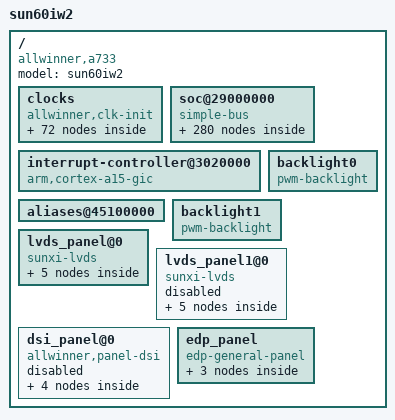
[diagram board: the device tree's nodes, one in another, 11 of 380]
/dts-v1/;

/ {
	model = "sun60iw2";
	compatible = "allwinner,a733", "arm,sun60iw2p1";
	#address-cells = <0x02>;
	#size-cells = <0x02>;

	clocks {
		compatible = "allwinner,clk-init";
		device_type = "clocks";
		#address-cells = <0x02>;
		#size-cells = <0x02>;
		ranges;
		reg = <0x00 0x2002000 0x00 0x2000 0x00 0x7010000 0x00 0x400>;

		pll_periph0 {
			#clock-cells = <0x00>;
			compatible = "allwinner,pll-clock";
			assigned-clock-rates = <0x23c34600>;
			lock-mode = "new";
			clock-output-names = "pll_periph0";
			phandle = <0x07>;
		};

		pll_periph0_2x {
			#clock-cells = <0x00>;
			compatible = "allwinner,pll-clock";
			lock-mode = "new";
			clock-output-names = "pll_periph0_2x";
			phandle = <0x01>;
		};

		pll_periph0_800m {
			#clock-cells = <0x00>;
			compatible = "allwinner,pll-clock";
			lock-mode = "new";
			clock-output-names = "pll_periph0_800m";
		};

		pll_periph0_600m {
			#clock-cells = <0x00>;
			compatible = "allwinner,fixed-factor-clock";
			clocks = <0x01>;
			clock-mult = <0x01>;
			clock-div = <0x02>;
			clock-output-names = "pll_periph0_600m";
			phandle = <0x02>;
		};

		pll_periph0_480m {
			#clock-cells = <0x00>;
			compatible = "allwinner,pll-clock";
			lock-mode = "new";
			clock-output-names = "pll_periph0_480m";
		};

		pll_periph0_400m {
			#clock-cells = <0x00>;
			compatible = "allwinner,fixed-factor-clock";
			clocks = <0x01>;
			clock-mult = <0x01>;
			clock-div = <0x03>;
			clock-output-names = "pll_periph0_400m";
			phandle = <0x03>;
		};

		pll_periph0_300m {
			#clock-cells = <0x00>;
			compatible = "allwinner,fixed-factor-clock";
			clocks = <0x02>;
			clock-mult = <0x01>;
			clock-div = <0x02>;
			clock-output-names = "pll_periph0_300m";
			phandle = <0x04>;
		};

		pll_periph0_200m {
			#clock-cells = <0x00>;
			compatible = "allwinner,fixed-factor-clock";
			clocks = <0x03>;
			clock-mult = <0x01>;
			clock-div = <0x02>;
			clock-output-names = "pll_periph0_200m";
		};

		pll_periph0_150m {
			#clock-cells = <0x00>;
			compatible = "allwinner,fixed-factor-clock";
			clocks = <0x04>;
			clock-mult = <0x01>;
			clock-div = <0x02>;
			clock-output-names = "pll_periph0_150m";
			phandle = <0x11>;
		};

		pll_periph1_2x {
			#clock-cells = <0x00>;
			compatible = "allwinner,pll-clock";
			lock-mode = "new";
			clock-output-names = "pll_periph1_2x";
			phandle = <0x05>;
		};

		pll_periph1_800m {
			#clock-cells = <0x00>;
			compatible = "allwinner,pll-clock";
			lock-mode = "new";
			clock-output-names = "pll_periph1_800m";
		};

		pll_periph1_600m {
			#clock-cells = <0x00>;
			compatible = "allwinner,fixed-factor-clock";
			clocks = <0x05>;
			clock-mult = <0x01>;
			clock-div = <0x02>;
			clock-output-names = "pll_periph1_600m";
			phandle = <0x06>;
		};

		pll_periph1_400m {
			#clock-cells = <0x00>;
			compatible = "allwinner,fixed-factor-clock";
			clocks = <0x05>;
			clock-mult = <0x01>;
			clock-div = <0x03>;
			clock-output-names = "pll_periph1_400m";
		};

		pll_periph1_300m {
			#clock-cells = <0x00>;
			compatible = "allwinner,fixed-factor-clock";
			clocks = <0x06>;
			clock-mult = <0x01>;
			clock-div = <0x02>;
			clock-output-names = "pll_periph1_300m";
		};

		pll_video2 {
			#clock-cells = <0x00>;
			compatible = "allwinner,pll-clock";
			lock-mode = "new";
			clock-output-names = "pll_video2";
			phandle = <0x0c>;
		};

		pll_periph0x2 {
			#clock-cells = <0x00>;
			compatible = "allwinner,fixed-factor-clock";
			clocks = <0x07>;
			clock-mult = <0x02>;
			clock-div = <0x01>;
			clock-output-names = "pll_periph0x2";
			phandle = <0x0a>;
		};

		pll_video0x4 {
			#clock-cells = <0x00>;
			compatible = "allwinner,pll-clock";
			lock-mode = "new";
			clock-output-names = "pll_video0x4";
		};

		pll_video0x3 {
			#clock-cells = <0x00>;
			compatible = "allwinner,pll-clock";
			lock-mode = "new";
			clock-output-names = "pll_video0x3";
		};

		pll_video1x4 {
			#clock-cells = <0x00>;
			compatible = "allwinner,pll-clock";
			lock-mode = "new";
			clock-output-names = "pll_video1x4";
			phandle = <0x0f>;
		};

		pll_video1x3 {
			#clock-cells = <0x00>;
			compatible = "allwinner,pll-clock";
			lock-mode = "new";
			clock-output-names = "pll_video1x3";
		};

		pll_video2x4 {
			#clock-cells = <0x00>;
			compatible = "allwinner,pll-clock";
			lock-mode = "new";
			clock-output-names = "pll_video2x4";
			phandle = <0x10>;
		};

		pll_dex4 {
			#clock-cells = <0x00>;
			compatible = "allwinner,pll-clock";
			lock-mode = "new";
			clock-output-names = "pll_dex4";
		};

		pll_dex3 {
			#clock-cells = <0x00>;
			compatible = "allwinner,pll-clock";
			lock-mode = "new";
			clock-output-names = "pll_dex3";
			phandle = <0x08>;
		};

		de0 {
			#clock-cells = <0x00>;
			compatible = "allwinner,periph-clock";
			clock-output-names = "de0";
			assigned-clock-parents = <0x08>;
			assigned-clock-rates = <0x23c34600>;
			assigned-clocks = <0x09>;
			phandle = <0x09>;
		};

		de_rst_sys {
			#clock-cells = <0x00>;
			compatible = "allwinner,periph-clock";
			clock-output-names = "de_rst_sys";
		};

		ee {
			#clock-cells = <0x00>;
			compatible = "allwinner,periph-clock";
			assigned-clock-parents = <0x0a>;
			assigned-clock-rates = <0x11e1a300>;
			assigned-clocks = <0x0b>;
			clock-output-names = "ee";
			phandle = <0x0b>;
		};

		panel {
			#clock-cells = <0x00>;
			compatible = "allwinner,periph-clock";
			assigned-clock-parents = <0x0c>;
			assigned-clock-rates = <0x1c9c380>;
			assigned-clocks = <0x0d>;
			clock-output-names = "panel";
			phandle = <0x0d>;
		};

		edp {
			#clock-cells = <0x00>;
			compatible = "allwinner,periph-clock";
			assigned-clocks = <0x0e>;
			assigned-clock-parents = <0x0f>;
			clock-output-names = "edp";
			phandle = <0x0e>;
		};

		sdmmc0_mod {
			#clock-cells = <0x00>;
			compatible = "allwinner,periph-clock";
			clock-output-names = "sdmmc0_mod";
			phandle = <0x99>;
		};

		sdmmc0_bus {
			#clock-cells = <0x00>;
			compatible = "allwinner,periph-clock";
			clock-output-names = "sdmmc0_bus";
			phandle = <0x9b>;
		};

		sdmmc0_rst {
			#clock-cells = <0x00>;
			compatible = "allwinner,periph-clock";
			clock-output-names = "sdmmc0_rst";
			phandle = <0x9a>;
		};

		sdmmc1_mod {
			#clock-cells = <0x00>;
			compatible = "allwinner,periph-clock";
			clock-output-names = "sdmmc1_mod";
		};

		sdmmc2_mod {
			#clock-cells = <0x00>;
			compatible = "allwinner,periph-clock";
			clock-output-names = "sdmmc2_mod";
			phandle = <0x9c>;
		};

		sdmmc2_bus {
			#clock-cells = <0x00>;
			compatible = "allwinner,periph-clock";
			clock-output-names = "sdmmc2_bus";
			phandle = <0x9e>;
		};

		sdmmc2_rst {
			#clock-cells = <0x00>;
			compatible = "allwinner,periph-clock";
			clock-output-names = "sdmmc2_rst";
			phandle = <0x9d>;
		};

		sdmmc3_mod {
			#clock-cells = <0x00>;
			compatible = "allwinner,periph-clock";
			clock-output-names = "sdmmc3_mod";
		};

		dpss_top0 {
			#clock-cells = <0x00>;
			compatible = "allwinner,periph-clock";
			clock-output-names = "dpss_top0";
			phandle = <0x63>;
		};

		dpss_top1 {
			#clock-cells = <0x00>;
			compatible = "allwinner,periph-clock";
			clock-output-names = "dpss_top1";
			phandle = <0x64>;
		};

		video_out0 {
			#clock-cells = <0x00>;
			compatible = "allwinner,periph-clock";
			clock-output-names = "video_out0";
		};

		video_out1 {
			#clock-cells = <0x00>;
			compatible = "allwinner,periph-clock";
			clock-output-names = "video_out1";
		};

		tcon_lcd0 {
			#clock-cells = <0x00>;
			compatible = "allwinner,periph-clock";
			clock-output-names = "tcon_lcd0";
			phandle = <0x65>;
		};

		tcon_lcd1 {
			#clock-cells = <0x00>;
			compatible = "allwinner,periph-clock";
			clock-output-names = "tcon_lcd1";
			phandle = <0x6b>;
		};

		tcon_lcd2 {
			#clock-cells = <0x00>;
			compatible = "allwinner,periph-clock";
			assigned-clock-parents = <0x10>;
			clock-output-names = "tcon_lcd2";
			phandle = <0x6d>;
		};

		tcon_tv0 {
			#clock-cells = <0x00>;
			compatible = "allwinner,periph-clock";
			clock-output-names = "tcon_tv0";
			phandle = <0x83>;
		};

		tcon_tv1 {
			#clock-cells = <0x00>;
			compatible = "allwinner,periph-clock";
			clock-output-names = "tcon_tv1";
			phandle = <0x86>;
		};

		lvds0 {
			#clock-cells = <0x00>;
			compatible = "allwinner,periph-clock";
			clock-output-names = "lvds0";
			phandle = <0x7b>;
		};

		lvds1 {
			#clock-cells = <0x00>;
			compatible = "allwinner,periph-clock";
			clock-output-names = "lvds1";
			phandle = <0x7f>;
		};

		mipi_dsi0 {
			#clock-cells = <0x00>;
			compatible = "allwinner,periph-clock";
			assigned-clock-parents = <0x11>;
			assigned-clock-rates = <0x8f0d180>;
			clock-output-names = "mipi_dsi0";
			phandle = <0x70>;
		};

		mipi_dsi1 {
			#clock-cells = <0x00>;
			compatible = "allwinner,periph-clock";
			assigned-clock-parents = <0x11>;
			assigned-clock-rates = <0x8f0d180>;
			clock-output-names = "mipi_dsi1";
			phandle = <0x78>;
		};

		mipi_dsc {
			#clock-cells = <0x00>;
			compatible = "allwinner,periph-clock";
			clock-output-names = "mipi_dsc";
			phandle = <0x71>;
		};

		mipi_dsi_combphy0 {
			#clock-cells = <0x00>;
			compatible = "allwinner,periph-clock";
			clock-output-names = "mipi_dsi_combphy0";
		};

		mipi_dsi_combphy1 {
			#clock-cells = <0x00>;
			compatible = "allwinner,periph-clock";
			clock-output-names = "mipi_dsi_combphy1";
		};

		hdmi_tv {
			#clock-cells = <0x00>;
			compatible = "allwinner,periph-clock";
			clock-output-names = "hdmi_tv";
		};

		hdmi_gate {
			#clock-cells = <0x00>;
			compatible = "allwinner,periph-clock";
			clock-output-names = "hdmi_gate";
			phandle = <0x8d>;
		};

		hdmi_sfr {
			#clock-cells = <0x00>;
			compatible = "allwinner,periph-clock";
			clock-output-names = "hdmi_sfr";
			phandle = <0x8e>;
		};

		hdmi_main_rst {
			#clock-cells = <0x00>;
			compatible = "allwinner,periph-clock";
			clock-output-names = "hdmi_main_rst";
			phandle = <0x8f>;
		};

		hdmi_hdcp_rst {
			#clock-cells = <0x00>;
			compatible = "allwinner,periph-clock";
			clock-output-names = "hdmi_hdcp_rst";
		};

		hdmi_sub_rst {
			#clock-cells = <0x00>;
			compatible = "allwinner,periph-clock";
			clock-output-names = "hdmi_sub_rst";
			phandle = <0x90>;
		};

		eink_panel {
			#clock-cells = <0x00>;
			compatible = "allwinner,periph-clock";
			clock-output-names = "eink_panel";
		};

		eink {
			#clock-cells = <0x00>;
			compatible = "allwinner,periph-clock";
			clock-output-names = "eink";
		};

		serdes_phy_cfg {
			#clock-cells = <0x00>;
			compatible = "allwinner,periph-clock";
			clock-output-names = "serdes_phy_cfg";
			phandle = <0x43>;
		};

		dcxo_serdes0_gate {
			#clock-cells = <0x00>;
			compatible = "allwinner,periph-clock";
			clock-output-names = "dcxo_serdes0_gate";
			phandle = <0x44>;
		};

		dcxo_serdes1_gate {
			#clock-cells = <0x00>;
			compatible = "allwinner,periph-clock";
			clock-output-names = "dcxo_serdes1_gate";
			phandle = <0x45>;
		};

		gmac0 {
			#clock-cells = <0x00>;
			compatible = "allwinner,periph-clock";
			clock-output-names = "gmac0";
			phandle = <0x93>;
		};

		gmac0_axi {
			#clock-cells = <0x00>;
			compatible = "allwinner,periph-clock";
			clock-output-names = "gmac0_axi";
			phandle = <0x92>;
		};

		gmac1 {
			#clock-cells = <0x00>;
			compatible = "allwinner,periph-clock";
			clock-output-names = "gmac1";
			phandle = <0x97>;
		};

		gmac1_axi {
			#clock-cells = <0x00>;
			compatible = "allwinner,periph-clock";
			clock-output-names = "gmac1_axi";
			phandle = <0x96>;
		};

		gmac0_mbus {
			#clock-cells = <0x00>;
			compatible = "allwinner,periph-clock";
			clock-output-names = "gmac0_mbus";
			phandle = <0x91>;
		};

		gmac1_mbus {
			#clock-cells = <0x00>;
			compatible = "allwinner,periph-clock";
			clock-output-names = "gmac1_mbus";
			phandle = <0x95>;
		};

		gmac0_phy {
			#clock-cells = <0x00>;
			compatible = "allwinner,periph-clock";
			clock-output-names = "gmac0_phy";
			assigned-clock-parents = <0x11>;
			assigned-clock-rates = <0x17d7840>;
			assigned-clocks = <0x12>;
			phandle = <0x12>;
		};

		gmac1_phy {
			#clock-cells = <0x00>;
			compatible = "allwinner,periph-clock";
			clock-output-names = "gmac1_phy";
			assigned-clock-parents = <0x11>;
			assigned-clock-rates = <0x17d7840>;
			assigned-clocks = <0x13>;
			phandle = <0x13>;
		};

		gmac_ptp {
			#clock-cells = <0x00>;
			compatible = "allwinner,periph-clock";
			clock-output-names = "gmac_ptp";
		};
	};

	soc@29000000 {
		compatible = "simple-bus";
		#address-cells = <0x02>;
		#size-cells = <0x02>;

		power_sply@4500000c {
			device_type = "power_sply";
			ntc_status = <0x02>;
			battery_exist = <0x00>;
		};

		power_delay@4500024 {
			device_type = "power_delay";
		};

		platform@45000004 {
			device_type = "platform";
			eraseflag = <0x01>;
			next_work = <0x03>;
			debug_mode = <0x04>;
		};

		target@45000008 {
			device_type = "target";
			boot_clock = <0x3f0>;
			storage_type = <0xffffffff>;
			burn_key = <0x01>;
			dragonboard_test = <0x00>;
		};

		charger0@45000010 {
			device_type = "charger0";
			pmu_safe_vol = <0xd48>;
			bat_bmp_type = <0x01>;
			ntc_cur = <0x3c>;
			safe_temp_H = <0x258>;
			safe_temp_L = <0xffffffce>;
			pmu_bat_temp_para1 = <0x11bd>;
			pmu_bat_temp_para2 = <0xaca>;
			pmu_bat_temp_para3 = <0x884>;
			pmu_bat_temp_para4 = <0x6c4>;
			pmu_bat_temp_para5 = <0x56a>;
			pmu_bat_temp_para6 = <0x45d>;
			pmu_bat_temp_para7 = <0x389>;
			pmu_bat_temp_para8 = <0x25e>;
			pmu_bat_temp_para9 = <0x19e>;
			pmu_bat_temp_para10 = <0x122>;
			pmu_bat_temp_para11 = <0xf4>;
			pmu_bat_temp_para12 = <0xcd>;
			pmu_bat_temp_para13 = <0xb0>;
			pmu_bat_temp_para14 = <0x96>;
			pmu_bat_temp_para15 = <0x6f>;
			pmu_bat_temp_para16 = <0x53>;
		};

		card_boot@45000014 {
			device_type = "card_boot";
			logical_start = <0xa000>;
			boot_work_delay = <0x82>;
			boot_work_times = <0x03>;
			sprite_gpio0 = <0x14 0x08 0x09 0x01 0xffffffff 0xffffffff 0x00>;
		};

		gpio_bias@45000018 {
			device_type = "gpio_bias";
		};

		fastboot_key@4500001c {
			device_type = "fastboot_key";
			key_max = <0x2a>;
			key_min = <0x26>;
		};

		recovery_key@45000020 {
			device_type = "recovery_key";
			key_max = <0x1f>;
			key_min = <0x1c>;
		};

		adc_boot_recovery@45000024 {
			device_type = "adc_boot_recovery";
			recovery_adc_used = <0x01>;
			recovery_adc_channel = <0x00>;
			press_mode_enable = <0x01>;
			short_press_mode = <0x00>;
			long_press_mode = <0x02>;
			key_press_time = <0x7d0>;
			key_min = <0x09>;
			key_max = <0x0b>;
		};

		gpadc_boot_recovery@45000024 {
			device_type = "gpadc_boot_recovery";
			recovery_adc_used = <0x01>;
			recovery_adc_channel = <0x09>;
			press_mode_enable = <0x01>;
			short_press_mode = <0x00>;
			long_press_mode = <0x03>;
			key_press_time = <0x1388>;
			key_min = <0x1c7>;
			key_max = <0x1f4>;
		};

		key_boot_recovery@45000028 {
			device_type = "key_boot_recovery";
		};

		pinctrl@0300b000 {
			compatible = "allwinner,sun60iw2p1-pinctrl";
			device_type = "pio";
			gpio-controller;
			#size-cells = <0x00>;
			#gpio-cells = <0x06>;
			input-debounce = <0x00 0x00 0x00 0x00 0x00 0x00 0x00 0x00 0x00>;
			phandle = <0x14>;

			pinctrl@07025000 {

				s_twi0@0 {
					allwinner,pins = "PL0", "PL1";
					allwinner,pname = "s_twi0_scl", "s_twi0_sda";
					allwinner,function = "s_twi0";
					allwinner,muxsel = <0x02>;
					allwinner,drive = <0x01>;
					allwinner,pull = <0x01>;
					phandle = <0x15>;
				};

				s_twi0@1 {
					allwinner,pins = "PL0", "PL1";
					allwinner,function = "gpio_out";
					allwinner,muxsel = <0x01>;
					allwinner,drive = <0x01>;
					allwinner,pull = <0x01>;
					phandle = <0x16>;
				};
			};

			sdc0@0 {
				allwinner,pins = "PF0", "PF1", "PF3", "PF4", "PF5";
				allwinner,function = "sdc0";
				allwinner,muxsel = <0x02>;
				allwinner,drive = <0x00>;
				allwinner,pull = <0x01>;
				phandle = <0x3d>;
			};

			sdc0@1 {
				allwinner,pins = "PF2";
				allwinner,function = "sdc0";
				allwinner,muxsel = <0x02>;
				allwinner,drive = <0x02>;
				allwinner,pull = <0x01>;
				phandle = <0x3e>;
			};

			sdc0@2 {
				allwinner,pins = "PF0", "PF1", "PF2", "PF3", "PF4", "PF5";
				allwinner,function = "uart0_jtag";
				allwinner,muxsel = <0x03>;
				allwinner,drive = <0x00>;
				allwinner,pull = <0x01>;
			};

			sdc2@0 {
				allwinner,pins = "PC6", "PC8", "PC9", "PC10", "PC11", "PC13", "PC14", "PC15", "PC16";
				allwinner,function = "sdc3";
				allwinner,muxsel = <0x04>;
				allwinner,drive = <0x01>;
				allwinner,pull = <0x01>;
				phandle = <0x3f>;
			};

			sdc2@1 {
				allwinner,pins = "PC1", "PC5";
				allwinner,function = "sdc3";
				allwinner,muxsel = <0x04>;
				allwinner,drive = <0x03>;
				allwinner,pull = <0x01>;
				phandle = <0x41>;
			};

			sdc2@2 {
				allwinner,pins = "PC0";
				allwinner,function = "sdc3";
				allwinner,muxsel = <0x04>;
				allwinner,drive = <0x03>;
				allwinner,pull = <0x02>;
				phandle = <0x40>;
			};

			nand0@0 {
			};

			nand0@1 {
			};

			nand0@2 {
			};

			spi0@0 {
			};

			spi0@1 {
			};

			spi0@2 {
			};

			spif@0 {
			};

			spif@1 {
			};

			spif@2 {
			};

			s_twi@0x07083000 {
				clock-frequency = <0x30d40>;
				pinctrl-0 = <0x15>;
				pinctrl-1 = <0x16>;
				twi-supply = <0x17>;
				status = "okay";

				pmu@34 {
				};

				pmu@36 {
					compatible = "x-powers,axp8191";
					reg = <0x36>;
					status = "okay";

					regulators@0 {

						dcdc1 {
							regulator-name = "axp8191-dcdc1";
							phandle = <0x18>;
						};

						dcdc2 {
							regulator-name = "axp8191-dcdc2";
							phandle = <0x8b>;
						};

						dcdc3 {
							regulator-name = "axp8191-dcdc3";
						};

						dcdc4 {
							regulator-name = "axp8191-dcdc4";
						};

						dcdc5 {
							regulator-name = "axp8191-dcdc5";
						};

						dcdc6 {
							regulator-name = "axp8191-dcdc6";
						};

						dcdc7 {
							regulator-name = "axp8191-dcdc7";
						};

						dcdc8 {
							regulator-name = "axp8191-dcdc8";
						};

						dcdc9 {
							regulator-name = "axp8191-dcdc9";
						};

						rtcldo {
							regulator-name = "axp8191-rtcldo";
						};

						aldo1 {
							regulator-name = "axp8191-aldo1";
						};

						aldo2 {
							regulator-name = "axp8191-aldo2";
						};

						aldo3 {
							regulator-name = "axp8191-aldo3";
							phandle = <0x17>;
						};

						aldo4 {
							regulator-name = "axp8191-aldo4";
						};

						aldo5 {
							regulator-name = "axp8191-aldo5";
						};

						aldo6 {
							regulator-name = "axp8191-aldo6";
						};

						dldo1 {
							regulator-name = "axp8191-dldo1";
						};

						dldo2 {
							regulator-name = "axp8191-dldo2";
							phandle = <0x8a>;
						};

						dldo3 {
							regulator-name = "axp8191-dldo3";
						};

						dldo4 {
							regulator-name = "axp8191-dldo4";
						};

						dldo5 {
							regulator-name = "axp8191-dldo5";
						};

						dldo6 {
							regulator-name = "axp8191-dldo6";
							phandle = <0x42>;
						};

						eldo1 {
							regulator-name = "axp8191-eldo1";
						};

						eldo2 {
							regulator-name = "axp8191-eldo2";
						};

						eldo3 {
							regulator-name = "axp8191-eldo3";
						};

						eldo4 {
							regulator-name = "axp8191-eldo4";
						};

						eldo5 {
							regulator-name = "axp8191-eldo5";
						};

						eldo6 {
							regulator-name = "axp8191-eldo6";
						};

						dc1sw1 {
							regulator-name = "axp8191-dc1sw1";
							swin-supply = <0x18>;
							regulator-always-on;
							regulator-boot-on;
							phandle = <0xa0>;
						};

						dc1sw2 {
							regulator-name = "axp8191-dc1sw2";
							swin-supply = <0x18>;
							regulator-always-on;
							regulator-boot-on;
						};
					};
				};
			};

			lvds0@0 {
				phandle = <0x7c>;
			};

			lvds0@1 {
				phandle = <0x7d>;
			};

			lvds1@0 {
			};

			lvds1@1 {
			};

			lvds2@0 {
				phandle = <0x80>;
			};

			lvds2@1 {
				phandle = <0x81>;
			};

			lvds3@0 {
			};

			lvds3@1 {
			};

			lcd1_lvds2link@0 {
			};

			lcd1_lvds2link@1 {
			};

			lvds2link@0 {
			};

			lvds2link@1 {
			};

			rgb24@0 {
			};

			rgb24@1 {
			};

			rgb18@0 {
			};

			rgb18@1 {
			};

			eink@0 {
			};

			eink@1 {
			};

			dsi4lane@0 {
			};

			dsi4lane@1 {
			};

			dsi0_4lane@0 {
				phandle = <0x73>;
			};

			dsi0_4lane@1 {
				phandle = <0x74>;
			};

			dsi1_4lane@0 {
			};

			dsi1_4lane@1 {
			};

			pwm0@0 {
			};

			pwm0@1 {
			};

			pwm1@0 {
			};

			pwm1@1 {
			};

			pwm2@0 {
			};

			pwm2@1 {
			};

			pwm3@0 {
			};

			pwm3@1 {
			};

			pwm4@0 {
				allwinner,pins = "PD22";
				allwinner,function = "pwm0_4";
				allwinner,muxsel = <0x02>;
				allwinner,drive = <0x03>;
				allwinner,pull = <0x02>;
				phandle = <0x23>;
			};

			pwm4@1 {
				allwinner,pins = "PD22";
				allwinner,function = "io_disabled";
				allwinner,muxsel = <0x0f>;
				allwinner,drive = <0x03>;
				allwinner,pull = <0x02>;
				phandle = <0x24>;
			};

			pwm16@0 {
				allwinner,pins = "PI15";
				allwinner,function = "pwm1_6";
				allwinner,muxsel = <0x05>;
				allwinner,drive = <0x03>;
				allwinner,pull = <0x02>;
				phandle = <0x2f>;
			};

			pwm16@1 {
				allwinner,pins = "PI15";
				allwinner,function = "io_disabled";
				allwinner,muxsel = <0x0f>;
				allwinner,drive = <0x03>;
				allwinner,pull = <0x02>;
				phandle = <0x30>;
			};

			pwm19@0 {
				allwinner,pins = "PE15";
				allwinner,function = "pwm1_9";
				allwinner,muxsel = <0x05>;
				allwinner,drive = <0x03>;
				allwinner,pull = <0x02>;
				phandle = <0x31>;
			};

			pwm19@1 {
				allwinner,pins = "PE15";
				allwinner,function = "io_disabled";
				allwinner,muxsel = <0x0f>;
				allwinner,drive = <0x03>;
				allwinner,pull = <0x02>;
				phandle = <0x32>;
			};

			gmac0@0 {
			};

			gmac0@1 {
			};

			gmac1@0 {
			};

			gmac1@1 {
			};
		};

		pwmchip0@2527000 {
			#pwm-cells = <0x03>;
			compatible = "allwinner,sunxi-pwm";
			reg = <0x00 0x2527000 0x00 0x400>;
			pwm-number = <0x0a>;
			pwm-base = <0x00>;
			sunxi-pwms = <0x19 0x1a 0x1b 0x1c 0x1d 0x1e 0x1f 0x20 0x21 0x22>;
		};

		pwm0@2527010 {
			#pwm-cells = <0x03>;
			compatible = "allwinner,sunxi-pwm0";
			reg = <0x00 0x2527010 0x00 0x04>;
			reg_base = <0x2527000>;
			status = "disabled";
			phandle = <0x19>;
		};

		pwm1@2527011 {
			#pwm-cells = <0x03>;
			compatible = "allwinner,sunxi-pwm1";
			reg = <0x00 0x2527011 0x00 0x04>;
			reg_base = <0x2527000>;
			status = "disabled";
			phandle = <0x1a>;
		};

		pwm2@2527012 {
			#pwm-cells = <0x03>;
			compatible = "allwinner,sunxi-pwm2";
			reg = <0x00 0x2527012 0x00 0x04>;
			reg_base = <0x2527000>;
			status = "disabled";
			phandle = <0x1b>;
		};

		pwm3@2527013 {
			#pwm-cells = <0x03>;
			compatible = "allwinner,sunxi-pwm3";
			reg = <0x00 0x2527013 0x00 0x04>;
			reg_base = <0x2527000>;
			status = "disabled";
			phandle = <0x1c>;
		};

		pwm4@2527014 {
			#pwm-cells = <0x03>;
			compatible = "allwinner,sunxi-pwm4";
			reg = <0x00 0x2527014 0x00 0x04>;
			reg_base = <0x2527000>;
			status = "okay";
			pinctrl-names = "active", "sleep";
			pinctrl-0 = <0x23>;
			pinctrl-1 = <0x24>;
			phandle = <0x1d>;
		};

		pwm5@2527015 {
			#pwm-cells = <0x03>;
			compatible = "allwinner,sunxi-pwm5";
			reg = <0x00 0x2527015 0x00 0x04>;
			reg_base = <0x2527000>;
			status = "disabled";
			phandle = <0x1e>;
		};

		pwm6@2527016 {
			#pwm-cells = <0x03>;
			compatible = "allwinner,sunxi-pwm6";
			reg = <0x00 0x2527016 0x00 0x04>;
			reg_base = <0x2527000>;
			status = "disabled";
			phandle = <0x1f>;
		};

		pwm7@2527017 {
			#pwm-cells = <0x03>;
			compatible = "allwinner,sunxi-pwm7";
			reg = <0x00 0x2527017 0x00 0x04>;
			reg_base = <0x2527000>;
			status = "disabled";
			phandle = <0x20>;
		};

		pwm8@2527018 {
			#pwm-cells = <0x03>;
			compatible = "allwinner,sunxi-pwm8";
			reg = <0x00 0x2527018 0x00 0x04>;
			reg_base = <0x2527000>;
			status = "disabled";
			phandle = <0x21>;
		};

		pwm9@2527019 {
			#pwm-cells = <0x03>;
			compatible = "allwinner,sunxi-pwm9";
			reg = <0x00 0x2527019 0x00 0x04>;
			reg_base = <0x2527000>;
			status = "disabled";
			phandle = <0x22>;
		};

		pwmchip1@2528000 {
			#pwm-cells = <0x03>;
			compatible = "allwinner,sunxi-pwm";
			reg = <0x00 0x2528000 0x00 0x400>;
			pwm-number = <0x0a>;
			pwm-base = <0x0a>;
			sunxi-pwms = <0x25 0x26 0x27 0x28 0x29 0x2a 0x2b 0x2c 0x2d 0x2e>;
		};

		pwm10@2528010 {
			#pwm-cells = <0x03>;
			compatible = "allwinner,sunxi-pwm10";
			reg = <0x00 0x2528010 0x00 0x04>;
			reg_base = <0x2528000>;
			status = "disabled";
			phandle = <0x25>;
		};

		pwm11@2528011 {
			#pwm-cells = <0x03>;
			compatible = "allwinner,sunxi-pwm11";
			reg = <0x00 0x2528011 0x00 0x04>;
			reg_base = <0x2528000>;
			status = "disabled";
			phandle = <0x26>;
		};

		pwm12@2528012 {
			#pwm-cells = <0x03>;
			compatible = "allwinner,sunxi-pwm12";
			reg = <0x00 0x2528012 0x00 0x04>;
			reg_base = <0x2528000>;
			status = "disabled";
			phandle = <0x27>;
		};

		pwm13@2528013 {
			#pwm-cells = <0x03>;
			compatible = "allwinner,sunxi-pwm13";
			reg = <0x00 0x2528013 0x00 0x04>;
			reg_base = <0x2528000>;
			status = "disabled";
			phandle = <0x28>;
		};

		pwm14@2528014 {
			#pwm-cells = <0x03>;
			compatible = "allwinner,sunxi-pwm14";
			reg = <0x00 0x2528014 0x00 0x04>;
			reg_base = <0x2528000>;
			status = "disabled";
			phandle = <0x29>;
		};

		pwm15@2528015 {
			#pwm-cells = <0x03>;
			compatible = "allwinner,sunxi-pwm15";
			reg = <0x00 0x2528015 0x00 0x04>;
			reg_base = <0x2528000>;
			status = "disabled";
			phandle = <0x2a>;
		};

		pwm16@2528016 {
			#pwm-cells = <0x03>;
			compatible = "allwinner,sunxi-pwm16";
			reg = <0x00 0x2528016 0x00 0x04>;
			reg_base = <0x2528000>;
			status = "disabled";
			pinctrl-names = "active", "sleep";
			pinctrl-0 = <0x2f>;
			pinctrl-1 = <0x30>;
			phandle = <0x2b>;
		};

		pwm17@2528017 {
			#pwm-cells = <0x03>;
			compatible = "allwinner,sunxi-pwm17";
			reg = <0x00 0x2528017 0x00 0x04>;
			reg_base = <0x2528000>;
			status = "disabled";
			phandle = <0x2c>;
		};

		pwm18@2528018 {
			#pwm-cells = <0x03>;
			compatible = "allwinner,sunxi-pwm18";
			reg = <0x00 0x2528018 0x00 0x04>;
			reg_base = <0x2528000>;
			status = "disabled";
			phandle = <0x2d>;
		};

		pwm19@2528019 {
			#pwm-cells = <0x03>;
			compatible = "allwinner,sunxi-pwm19";
			reg = <0x00 0x2528019 0x00 0x04>;
			reg_base = <0x2528000>;
			status = "okay";
			pinctrl-names = "active", "sleep";
			pinctrl-0 = <0x31>;
			pinctrl-1 = <0x32>;
			phandle = <0x2e>;
		};

		spwm0@7023000 {
			#pwm-cells = <0x03>;
			compatible = "allwinner,sunxi-pwm";
			reg = <0x00 0x7023000 0x00 0x400>;
			pwm-number = <0x0a>;
			pwm-base = <0x14>;
			sunxi-pwms = <0x33 0x34 0x35 0x36 0x37 0x38 0x39 0x3a 0x3b 0x3c>;
		};

		pwm20@7023010 {
			#pwm-cells = <0x03>;
			compatible = "allwinner,sunxi-pwm20";
			reg = <0x00 0x7023010 0x00 0x04>;
			reg_base = <0x7023000>;
			status = "disabled";
			phandle = <0x33>;
		};

		pwm21@7023011 {
			#pwm-cells = <0x03>;
			compatible = "allwinner,sunxi-pwm21";
			reg = <0x00 0x7023011 0x00 0x04>;
			reg_base = <0x7023000>;
			status = "disabled";
			phandle = <0x34>;
		};

		pwm22@7023012 {
			#pwm-cells = <0x03>;
			compatible = "allwinner,sunxi-pwm22";
			reg = <0x00 0x7023012 0x00 0x04>;
			reg_base = <0x7023000>;
			status = "disabled";
			phandle = <0x35>;
		};

		pwm23@7023013 {
			#pwm-cells = <0x03>;
			compatible = "allwinner,sunxi-pwm23";
			reg = <0x00 0x7023013 0x00 0x04>;
			reg_base = <0x7023000>;
			status = "disabled";
			phandle = <0x36>;
		};

		pwm24@7023014 {
			#pwm-cells = <0x03>;
			compatible = "allwinner,sunxi-pwm24";
			reg = <0x00 0x7023014 0x00 0x04>;
			reg_base = <0x7023000>;
			status = "disabled";
			phandle = <0x37>;
		};

		pwm25@7023015 {
			#pwm-cells = <0x03>;
			compatible = "allwinner,sunxi-pwm25";
			reg = <0x00 0x7023015 0x00 0x04>;
			reg_base = <0x7023000>;
			status = "disabled";
			phandle = <0x38>;
		};

		pwm26@7023016 {
			#pwm-cells = <0x03>;
			compatible = "allwinner,sunxi-pwm26";
			reg = <0x00 0x7023016 0x00 0x04>;
			reg_base = <0x7023000>;
			status = "disabled";
			phandle = <0x39>;
		};

		pwm27@7023017 {
			#pwm-cells = <0x03>;
			compatible = "allwinner,sunxi-pwm27";
			reg = <0x00 0x7023017 0x00 0x04>;
			reg_base = <0x7023000>;
			status = "disabled";
			phandle = <0x3a>;
		};

		pwm28@7023018 {
			#pwm-cells = <0x03>;
			compatible = "allwinner,sunxi-pwm28";
			reg = <0x00 0x7023018 0x00 0x04>;
			reg_base = <0x7023000>;
			status = "disabled";
			phandle = <0x3b>;
		};

		pwm29@7023019 {
			#pwm-cells = <0x03>;
			compatible = "allwinner,sunxi-pwm29";
			reg = <0x00 0x7023019 0x00 0x04>;
			reg_base = <0x7023000>;
			status = "disabled";
			phandle = <0x3c>;
		};

		card0_boot_para@2 {
			device_type = "card0_boot_para";
			card_ctrl = <0x00>;
			card_high_speed = <0x01>;
			card_line = <0x04>;
			clk_mmc = "sdmmc0_mod";
			pll-0 = "hosc";
			pll-1 = "pll_periph1_400m";
			pll-2 = "pll_periph1_300m";
			pinctrl-0 = <0x3d 0x3e>;
			clk_type = "typ1";
		};

		card2_boot_para@3 {
			device_type = "card2_boot_para";
			reg = <0x00 0x03 0x00 0x00>;
			card_ctrl = <0x02>;
			card_high_speed = <0x01>;
			card_line = <0x08>;
			clk_mmc = "sdmmc2_mod";
			pll-0 = "hosc";
			pll-1 = "pll_periph1_800m";
			pll-2 = "pll_periph1_600m";
			pinctrl-0 = <0x3f 0x40 0x41>;
			sdc_ex_dly_used = <0x02>;
			sdc_tm4_hs200_max_freq = <0xc8>;
			sdc_tm4_hs400_max_freq = <0xc8>;
			sdc_tm4_win_th = <0x07>;
			sdc_io_1v8 = <0x01>;
			sdc_mbus = <0x01>;
			sdc_type = "tm4";
			clk_type = "typ1";
		};

		sid@3006000 {
			device_type = "sid";
			sid-supply = <0x42>;
			voltage = <0x708>;
			power_supply = "dldo6";
		};

		nand0@04011000 {
			device_type = "nand0";
		};

		spi@2540000 {
			#address-cells = <0x01>;
			#size-cells = <0x00>;
			compatible = "allwinner,sun20i-spi";
			device_type = "spi0";
			reg = <0x00 0x2540000 0x00 0x300>;
		};

		spif@4f00000 {
			#address-cells = <0x01>;
			#size-cells = <0x00>;
			compatible = "allwinner,sun55i-spif";
			device_type = "spif";
			reg = <0x00 0x47f0000 0x00 0x1000>;
		};

		serdes@6c00000 {
			compatible = "allwinner,cadence-combophy";
			reg = <0x00 0x6c00000 0x00 0x400 0x00 0x6c06000 0x00 0x2000 0x00 0x709016c 0x00 0x04>;
			clocks = <0x43 0x44 0x45>;
			clock-names = "serdes-clk", "dcxo-serdes0-clk", "dcxo-serdes1-clk";
			#address-cells = <0x02>;
			#size-cells = <0x02>;
			ranges;
			status = "okay";

			combo-phy0@6c01000 {
				reg = <0x00 0x6c01000 0x00 0xa00 0x00 0x6c80000 0x00 0x20000>;
				#phy-cells = <0x01>;
				lane_invert = <0x00 0x00 0x00 0x00>;
				lane_remap = <0x02 0x03 0x00 0x01>;
				phandle = <0x89>;
			};

			combo-phy1@6c02000 {
				reg = <0x00 0x6c02000 0x00 0xa00 0x00 0x6ca0000 0x00 0x20000>;
				#phy-cells = <0x01>;
				phandle = <0x46>;
			};

			aux-hpd@6c01e00 {
				reg = <0x00 0x6c01e00 0x00 0x200>;
				#phy-cells = <0x01>;
				phandle = <0x88>;
			};
		};

		pcie@6000000 {
			compatible = "allwinner,sunxi-pcie-v300-rc";
			#address-cells = <0x03>;
			#size-cells = <0x02>;
			bus-range = <0x00 0xff>;
			reg = <0x00 0x6000000 0x00 0x480000>;
			reg-names = "dbi";
			device_type = "pci";
			ranges = <0x800 0x00 0x20000000 0x00 0x20000000 0x00 0x1000000 0x81000000 0x00 0x21000000 0x00 0x21000000 0x00 0x1000000 0x82000000 0x00 0x22000000 0x00 0x22000000 0x00 0xe000000>;
			num-lanes = <0x01>;
			phys = <0x46 0x02>;
			phy-names = "pcie-phy";
			#interrupt-cells = <0x01>;
			num-edma = <0x04>;
			max-link-speed = <0x03>;
			num-ib-windows = <0x10>;
			num-ob-windows = <0x10>;
			linux,pci-domain = <0x00>;
			status = "okay";
			pcie1v8_supply = "dldo2";
			pcie3v3_supply = "dc1sw2";
		};

		sunxi-drm {
			compatible = "allwinner,sunxi-drm";
			fb_base = <0x00>;
			status = "okay";

			route {

				disp0_lvds0 {
					enable = <0x00>;
					status = "disabled";
					endpoints = <0x47 0x48>;
					logo,uboot = "bootlogo.bmp";
				};

				disp0_lvds1 {
					enable = <0x00>;
					status = "disabled";
					endpoints = <0x49 0x4a>;
					logo,uboot = "bootlogo.bmp";
				};

				disp0_rgb0 {
					enable = <0x00>;
					status = "disabled";
					endpoints = <0x47 0x4b>;
					logo,uboot = "bootlogo.bmp";
				};

				disp0_rgb1 {
					enable = <0x00>;
					status = "disabled";
					endpoints = <0x49 0x4c>;
					logo,uboot = "bootlogo.bmp";
				};

				disp0_dsi0 {
					enable = <0x00>;
					status = "disabled";
					endpoints = <0x47 0x4d>;
					logo,uboot = "bootlogo.bmp";
				};

				disp0_dsi1 {
					enable = <0x00>;
					status = "disabled";
					endpoints = <0x4e 0x4f>;
					logo,uboot = "bootlogo.bmp";
				};

				disp0_edp0 {
					enable = <0x00>;
					status = "disabled";
					endpoints = <0x50 0x51>;
					logo,uboot = "bootlogo.bmp";
				};

				disp0_hdmi0 {
					enable = <0x01>;
					status = "okay";
					endpoints = <0x52 0x53>;
					logo,uboot = "bootlogo.bmp";
				};

				disp1_lvds0 {
					enable = <0x01>;
					status = "disabled";
					endpoints = <0x54 0x48>;
					logo,uboot = "bootlogo.bmp";
				};

				disp1_lvds1 {
					enable = <0x00>;
					status = "disabled";
					endpoints = <0x55 0x4a>;
					logo,uboot = "bootlogo.bmp";
				};

				disp1_rgb0 {
					enable = <0x00>;
					status = "disabled";
					endpoints = <0x54 0x4b>;
					logo,uboot = "bootlogo.bmp";
				};

				disp1_rgb1 {
					enable = <0x00>;
					status = "disabled";
					endpoints = <0x55 0x4c>;
					logo,uboot = "bootlogo.bmp";
				};

				disp1_dsi0 {
					enable = <0x00>;
					status = "disabled";
					endpoints = <0x54 0x4d>;
					logo,uboot = "bootlogo.bmp";
				};

				disp1_dsi1 {
					enable = <0x00>;
					status = "disabled";
					endpoints = <0x56 0x4f>;
					logo,uboot = "bootlogo.bmp";
				};

				disp1_edp0 {
					enable = <0x00>;
					status = "disabled";
					endpoints = <0x57 0x51>;
					logo,uboot = "bootlogo.bmp";
				};

				disp1_hdmi0 {
					enable = <0x00>;
					status = "disabled";
					endpoints = <0x58 0x53>;
					logo,uboot = "bootlogo.bmp";
				};
			};
		};

		de@5000000 {
			compatible = "allwinner,display-engine-v352";
			reg = <0x00 0x5000000 0x00 0x400000>;
			interrupts = <0x00 0x32 0x04 0x00 0x22 0x04>;
			clocks = <0x09>;
			clock-names = "clk_de";
			status = "okay";
			chn_cfg_mode = <0x02>;

			ports {
				#address-cells = <0x01>;
				#size-cells = <0x00>;

				port@0 {
					reg = <0x00>;
					#address-cells = <0x01>;
					#size-cells = <0x00>;

					endpoint@0 {
						reg = <0x00>;
						remote-endpoint = <0x59>;
						phandle = <0x47>;
					};

					endpoint@1 {
						reg = <0x01>;
						remote-endpoint = <0x5a>;
						phandle = <0x4e>;
					};

					endpoint@2 {
						reg = <0x02>;
						remote-endpoint = <0x5b>;
						phandle = <0x49>;
					};

					endpoint@3 {
						reg = <0x04>;
						remote-endpoint = <0x5c>;
						phandle = <0x52>;
					};

					endpoint@4 {
						reg = <0x05>;
						remote-endpoint = <0x5d>;
						phandle = <0x50>;
					};
				};

				port@1 {
					reg = <0x01>;
					#address-cells = <0x01>;
					#size-cells = <0x00>;

					endpoint@0 {
						reg = <0x00>;
						remote-endpoint = <0x5e>;
						phandle = <0x54>;
					};

					endpoint@1 {
						reg = <0x01>;
						remote-endpoint = <0x5f>;
						phandle = <0x56>;
					};

					endpoint@2 {
						reg = <0x02>;
						remote-endpoint = <0x60>;
						phandle = <0x55>;
					};

					endpoint@3 {
						reg = <0x04>;
						remote-endpoint = <0x61>;
						phandle = <0x58>;
					};

					endpoint@4 {
						reg = <0x05>;
						remote-endpoint = <0x62>;
						phandle = <0x57>;
					};
				};
			};
		};

		vo0@5500000 {
			compatible = "allwinner,tcon-top0";
			reg = <0x00 0x5500000 0x00 0x1000>;
			clocks = <0x63>;
			clock-names = "clk_bus_dpss_top";
			status = "okay";
			phandle = <0x66>;
		};

		vo1@5510000 {
			compatible = "allwinner,tcon-top1";
			reg = <0x00 0x5510000 0x00 0x1000>;
			clocks = <0x64>;
			clock-names = "clk_bus_dpss_top";
			status = "okay";
			phandle = <0x84>;
		};

		tcon0@5501000 {
			compatible = "allwinner,tcon-lcd";
			reg = <0x00 0x5501000 0x00 0x1000>;
			interrupts = <0x00 0x36 0x04>;
			clocks = <0x65>;
			clock-names = "clk_tcon";
			top = <0x66>;
			status = "okay";

			ports {
				#address-cells = <0x01>;
				#size-cells = <0x00>;

				port@0 {
					#address-cells = <0x01>;
					#size-cells = <0x00>;
					reg = <0x00>;

					endpoint@0 {
						reg = <0x00>;
						remote-endpoint = <0x47>;
						phandle = <0x59>;
					};

					endpoint@1 {
						reg = <0x01>;
						remote-endpoint = <0x54>;
						phandle = <0x5e>;
					};
				};

				port@1 {
					#address-cells = <0x01>;
					#size-cells = <0x00>;
					reg = <0x01>;

					endpoint@0 {
						reg = <0x00>;
						remote-endpoint = <0x67>;
						phandle = <0x4d>;
					};

					endpoint@1 {
						reg = <0x01>;
						remote-endpoint = <0x68>;
						phandle = <0x7a>;
					};

					endpoint@2 {
						reg = <0x02>;
						remote-endpoint = <0x69>;
						phandle = <0x48>;
					};

					endpoint@3 {
						reg = <0x03>;
						remote-endpoint = <0x6a>;
						phandle = <0x4b>;
					};
				};
			};
		};

		tcon1@5502000 {
			compatible = "allwinner,tcon-lcd";
			reg = <0x00 0x5502000 0x00 0x1000>;
			interrupts = <0x00 0x37 0x04>;
			clocks = <0x6b>;
			clock-names = "clk_tcon";
			top = <0x66>;
			status = "disabled";

			ports {
				#address-cells = <0x01>;
				#size-cells = <0x00>;

				port@0 {
					reg = <0x00>;
					#address-cells = <0x01>;
					#size-cells = <0x00>;

					endpoint@0 {
						reg = <0x00>;
						remote-endpoint = <0x4e>;
						phandle = <0x5a>;
					};

					endpoint@1 {
						reg = <0x01>;
						remote-endpoint = <0x56>;
						phandle = <0x5f>;
					};
				};

				port@1 {
					#address-cells = <0x01>;
					#size-cells = <0x00>;
					reg = <0x01>;

					endpoint@0 {
						reg = <0x00>;
						remote-endpoint = <0x6c>;
						phandle = <0x4f>;
					};
				};
			};
		};

		tcon2@5503000 {
			compatible = "allwinner,tcon-lcd";
			reg = <0x00 0x5503000 0x00 0x1000>;
			interrupts = <0x00 0x38 0x04>;
			clocks = <0x6d>;
			clock-names = "clk_tcon";
			top = <0x66>;
			status = "okay";

			ports {
				#address-cells = <0x01>;
				#size-cells = <0x00>;

				port@0 {
					#address-cells = <0x01>;
					#size-cells = <0x00>;
					reg = <0x00>;

					endpoint@0 {
						reg = <0x00>;
						remote-endpoint = <0x49>;
						phandle = <0x5b>;
					};

					endpoint@1 {
						reg = <0x01>;
						remote-endpoint = <0x55>;
						phandle = <0x60>;
					};
				};

				port@1 {
					#address-cells = <0x01>;
					#size-cells = <0x00>;
					reg = <0x01>;

					endpoint@0 {
						reg = <0x00>;
						remote-endpoint = <0x6e>;
						phandle = <0x4a>;
					};

					endpoint@1 {
						reg = <0x01>;
						remote-endpoint = <0x6f>;
						phandle = <0x4c>;
					};
				};
			};
		};

		phy@5507000 {
			compatible = "allwinner,sunxi-dsi-combo-phy0,sun60iw2";
			reg = <0x00 0x5507000 0x00 0x1ff>;
			clocks = <0x70>;
			clock-names = "phy_clk";
			#phy-cells = <0x00>;
			status = "okay";
			phandle = <0x72>;
		};

		dsi0@5506000 {
			compatible = "allwinner,dsi0";
			reg = <0x00 0x5506000 0x00 0xfff 0x00 0x5504000 0x00 0xfff>;
			interrupts = <0x00 0x3b 0x04>;
			clocks = <0x70 0x71>;
			clock-names = "dsi_clk", "dsc_clk";
			phys = <0x72>;
			phy-names = "combophy";
			status = "disabled";
			pinctrl-0 = <0x73>;
			pinctrl-1 = <0x74>;
			pinctrl-names = "active", "sleep";

			ports {
				#address-cells = <0x01>;
				#size-cells = <0x00>;

				port@0 {
					#address-cells = <0x01>;
					#size-cells = <0x00>;
					reg = <0x00>;

					endpoint@0 {
						reg = <0x00>;
						remote-endpoint = <0x4d>;
						phandle = <0x67>;
					};
				};

				port@1 {

					endpoint {
						remote-endpoint = <0x75>;
						phandle = <0x76>;
					};
				};
			};

			panel@0 {
				compatible = "allwinner,virtual-panel";
				status = "okay";
				reg = <0x00>;

				ports {

					port@0 {
						reg = <0x00>;

						endpoint@0 {
							reg = <0x00>;
							remote-endpoint = <0x76>;
							phandle = <0x75>;
						};
					};

					port@1 {
						reg = <0x01>;

						endpoint@0 {
							reg = <0x00>;
							remote-endpoint = <0x77>;
							phandle = <0xa8>;
						};
					};
				};
			};
		};

		phy@5509000 {
			compatible = "allwinner,sunxi-dsi-combo-phy1,sun60iw2";
			reg = <0x00 0x5509000 0x00 0x1ff>;
			clocks = <0x78>;
			clock-names = "phy_clk";
			#phy-cells = <0x00>;
			status = "disabled";
			phandle = <0x79>;
		};

		dsi1@5508000 {
			compatible = "allwinner,dsi1";
			reg = <0x00 0x5508000 0x00 0xfff>;
			interrupts = <0x00 0x3c 0x04>;
			clocks = <0x78>;
			clock-names = "dsi_clk";
			phys = <0x79>;
			phy-names = "combophy";
			status = "disabled";

			ports {
				#address-cells = <0x01>;
				#size-cells = <0x00>;

				port@0 {
					reg = <0x00>;
					#address-cells = <0x01>;
					#size-cells = <0x00>;

					endpoint@1 {
						reg = <0x00>;
						remote-endpoint = <0x4f>;
						phandle = <0x6c>;
					};

					endpoint@0 {
						reg = <0x01>;
						remote-endpoint = <0x7a>;
						phandle = <0x68>;
					};
				};
			};
		};

		rgb0@0001000 {
			compatible = "allwinner,rgb0";
			status = "disabled";

			ports {
				#address-cells = <0x01>;
				#size-cells = <0x00>;

				port@0 {
					#address-cells = <0x01>;
					#size-cells = <0x00>;
					reg = <0x00>;

					endpoint@0 {
						reg = <0x00>;
						remote-endpoint = <0x4b>;
						phandle = <0x6a>;
					};
				};
			};
		};

		lvds0@0001000 {
			compatible = "allwinner,lvds0";
			clocks = <0x7b>;
			clock-names = "clk_lvds";
			phys = <0x72 0x79>;
			phy-names = "combophy0", "combophy1";
			status = "okay";
			dual-channel = <0x00>;
			pinctrl-0 = <0x7c>;
			pinctrl-1 = <0x7d>;
			pinctrl-names = "active", "sleep";

			ports {
				#address-cells = <0x01>;
				#size-cells = <0x00>;

				port@0 {
					#address-cells = <0x01>;
					#size-cells = <0x00>;
					reg = <0x00>;

					endpoint@0 {
						reg = <0x00>;
						remote-endpoint = <0x48>;
						phandle = <0x69>;
					};
				};

				port@1 {
					reg = <0x01>;

					endpoint@0 {
						reg = <0x00>;
						remote-endpoint = <0x7e>;
						phandle = <0xa3>;
					};
				};
			};
		};

		rgb1@0001000 {
			compatible = "allwinner,rgb1";
			reg = <0x00>;
			status = "disabled";

			ports {
				#address-cells = <0x01>;
				#size-cells = <0x00>;

				port@0 {
					#address-cells = <0x01>;
					#size-cells = <0x00>;
					reg = <0x00>;

					endpoint@0 {
						reg = <0x00>;
						remote-endpoint = <0x4c>;
						phandle = <0x6f>;
					};
				};
			};
		};

		lvds1@0001000 {
			compatible = "allwinner,lvds1";
			clocks = <0x7f>;
			clock-names = "clk_lvds";
			status = "okay";
			dual-channel = <0x00>;
			pinctrl-0 = <0x80>;
			pinctrl-1 = <0x81>;
			pinctrl-names = "active", "sleep";

			ports {
				#address-cells = <0x01>;
				#size-cells = <0x00>;

				port@0 {
					#address-cells = <0x01>;
					#size-cells = <0x00>;
					reg = <0x00>;

					endpoint@0 {
						reg = <0x00>;
						remote-endpoint = <0x4a>;
						phandle = <0x6e>;
					};
				};

				port@1 {
					reg = <0x01>;

					endpoint@0 {
						reg = <0x00>;
						remote-endpoint = <0x82>;
						phandle = <0xa6>;
					};
				};
			};
		};

		tcon3@5730000 {
			compatible = "allwinner,tcon-tv";
			reg = <0x00 0x5730000 0x00 0x1000>;
			interrupts = <0x00 0x39 0x04>;
			clocks = <0x83>;
			clock-names = "rst_bus_tcon";
			top = <0x84>;
			status = "okay";

			ports {
				#address-cells = <0x01>;
				#size-cells = <0x00>;

				port@0 {
					#address-cells = <0x01>;
					#size-cells = <0x00>;
					reg = <0x00>;

					endpoint@0 {
						reg = <0x00>;
						remote-endpoint = <0x52>;
						phandle = <0x5c>;
					};

					endpoint@1 {
						reg = <0x01>;
						remote-endpoint = <0x58>;
						phandle = <0x61>;
					};
				};

				port@1 {
					#address-cells = <0x01>;
					#size-cells = <0x00>;
					reg = <0x01>;

					endpoint@0 {
						reg = <0x00>;
						remote-endpoint = <0x85>;
						phandle = <0x53>;
					};
				};
			};
		};

		tcon4@5731000 {
			compatible = "allwinner,tcon-tv";
			reg = <0x00 0x5731000 0x00 0x1000>;
			interrupts = <0x00 0x3a 0x04>;
			clocks = <0x0e 0x86>;
			clock-names = "clk_tcon", "clk_bus_tcon";
			top = <0x84>;
			status = "okay";

			ports {
				#address-cells = <0x01>;
				#size-cells = <0x00>;

				port@0 {
					reg = <0x00>;
					#address-cells = <0x01>;
					#size-cells = <0x00>;

					endpoint@0 {
						reg = <0x00>;
						remote-endpoint = <0x50>;
						phandle = <0x5d>;
					};

					endpoint@1 {
						reg = <0x01>;
						remote-endpoint = <0x57>;
						phandle = <0x62>;
					};
				};

				port@1 {
					#address-cells = <0x01>;
					#size-cells = <0x00>;
					reg = <0x01>;

					endpoint@0 {
						reg = <0x00>;
						remote-endpoint = <0x87>;
						phandle = <0x51>;
					};
				};
			};
		};

		edp0@5720000 {
			compatible = "allwinner,drm-edp";
			reg = <0x00 0x5740000 0x00 0x1000 0x00 0x5760000 0x00 0x20>;
			interrupts = <0x00 0x3e 0x04>;
			clocks = <0x0e>;
			clock-names = "clk_edp";
			phys = <0x88 0x63 0x89 0x06>;
			phy-names = "aux-phy", "dp-phy";
			pclk_limit = <0x30d40>;
			status = "okay";
			edp_colordepth = <0x08>;
			edp_color_fmt = <0x00>;
			edp_pixel_mode = <0x01>;
			vcc-edp-supply = <0x8a>;
			vdd-edp-supply = <0x8b>;

			ports {
				#address-cells = <0x01>;
				#size-cells = <0x00>;

				port@0 {
					#address-cells = <0x01>;
					#size-cells = <0x00>;
					reg = <0x00>;

					endpoint@0 {
						reg = <0x00>;
						remote-endpoint = <0x51>;
						phandle = <0x87>;
					};
				};

				port@1 {
					#address-cells = <0x01>;
					#size-cells = <0x00>;
					reg = <0x01>;

					endpoint@0 {
						reg = <0x00>;
						remote-endpoint = <0x8c>;
						phandle = <0xa9>;
					};
				};
			};
		};

		hdmi0@5520000 {
			compatible = "allwinner,sunxi-hdmi";
			reg = <0x00 0x5520000 0x00 0x100000>;
			interrupts = <0x00 0x3d 0x04>;
			clocks = <0x8d 0x8e 0x8f 0x90>;
			clock-names = "clk_hdmi", "clk_hdmi_24M", "rst_main", "rst_sub";
			assigned-clocks = <0x8d>;
			assigned-clock-rates = <0x00 0x00>;
			status = "okay";
			dcdc2-supply = <0x8b>;
			dldo2-supply = <0x8a>;
			hdmi_power0 = "dcdc2-supply";
			hdmi_power1 = "dldo2-supply";
			uhdmi_power_count = <0x02>;
			uhdmi_fast_output = <0x00>;
			uhdmi_resistor_select = <0x01>;
			snps_phy = <0x61a8 0x2d519 0x07 0x8160 0x8188 0x2d519 0x2d519 0x07 0x8160 0x8198 0x2d519 0x53020 0x04 0x8040 0x8e85 0x53020 0x927c0 0x00 0x80c0 0x82f6>;

			ports {
				#address-cells = <0x01>;
				#size-cells = <0x00>;

				port@0 {
					#address-cells = <0x01>;
					#size-cells = <0x00>;
					reg = <0x00>;

					endpoint@0 {
						reg = <0x00>;
						remote-endpoint = <0x53>;
						phandle = <0x85>;
					};
				};
			};
		};

		ethernet@4500000 {
			compatible = "allwinner,sunxi-gmac";
			reg = <0x00 0x4500000 0x00 0x8000 0x00 0x4508000 0x00 0x8000>;
			clocks = <0x91 0x92 0x93 0x12>;
			clock-names = "pclk", "axi", "ahb", "phy";
			aw,gmac-version = "210";
			phy-handle = <0x94>;
			status = "disabled";

			mdio0 {
				#address-cells = <0x01>;
				#size-cells = <0x00>;
				compatible = "snps,dwmac-mdio";

				ethernet-phy@0 {
					reg = <0x01>;
					phandle = <0x94>;
				};
			};
		};

		ethernet@4510000 {
			compatible = "allwinner,sunxi-gmac";
			reg = <0x00 0x4510000 0x00 0x8000 0x00 0x4518000 0x00 0x8000>;
			clocks = <0x95 0x96 0x97 0x13>;
			clock-names = "pclk", "axi", "ahb", "phy";
			aw,gmac-version = "210";
			phy-handle = <0x98>;
			status = "disabled";

			mdio1 {
				#address-cells = <0x01>;
				#size-cells = <0x00>;
				compatible = "snps,dwmac-mdio";

				ethernet-phy@1 {
					reg = <0x01>;
					phandle = <0x98>;
				};
			};
		};

		clk_test@0x12345 {
			clocks = <0x99 0x9a 0x9b 0x9c 0x9d 0x9e>;
			status = "okay";
		};
	};

	interrupt-controller@3020000 {
		compatible = "arm,cortex-a15-gic", "arm,cortex-a9-gic";
		#interrupt-cells = <0x03>;
		#address-cells = <0x00>;
		device_type = "gic";
		interrupt-controller;
		reg = <0x00 0x3021000 0x00 0x1000 0x00 0x3022000 0x00 0x2000 0x00 0x3024000 0x00 0x2000 0x00 0x3026000 0x00 0x2000>;
		interrupts = <0x01 0x09 0xf04>;
		interrupt-parent = <0x9f>;
		phandle = <0x9f>;
	};

	aliases@45100000 {
		pwmchip0 = "/soc@29000000/pwmchip0@2527000";
		pwmchip1 = "/soc@29000000/pwmchip1@2528000";
		pwmchip2 = "/soc@29000000/spwm0@7023000";
		pwm0 = "/soc@29000000/pwm0@2527010";
		pwm1 = "/soc@29000000/pwm1@2527011";
		pwm2 = "/soc@29000000/pwm2@2527012";
		pwm3 = "/soc@29000000/pwm3@2527013";
		pwm4 = "/soc@29000000/pwm4@2527014";
		pwm16 = "/soc@29000000/pwm16@2528016";
		pwm19 = "/soc@29000000/pwm19@2528019";
		twi6 = "/soc@29000000/pinctrl@0300b000/s_twi@0x07083000";
		pmu0 = "/soc@29000000/pinctrl@0300b000/s_twi@0x07083000/pmu@34";
		spi0 = "/soc@29000000/spi@2540000";
		ethernet0 = "/soc@29000000/ethernet@4500000";
		ethernet1 = "/soc@29000000/ethernet@4510000";
	};

	backlight0 {
		compatible = "pwm-backlight";
		status = "okay";
		brightness-levels = <0x00 0x01 0x02 0x03 0x04 0x05 0x06 0x07 0x08 0x09 0x0a 0x0b 0x0c 0x0d 0x0e 0x0f 0x10 0x11 0x12 0x13 0x14 0x15 0x16 0x17 0x18 0x19 0x1a 0x1b 0x1c 0x1d 0x1e 0x1f 0x20 0x21 0x22 0x23 0x24 0x25 0x26 0x27 0x28 0x29 0x2a 0x2b 0x2c 0x2d 0x2e 0x2f 0x30 0x31 0x32 0x33 0x34 0x35 0x36 0x37 0x38 0x39 0x3a 0x3b 0x3c 0x3d 0x3e 0x3f 0x40 0x41 0x42 0x43 0x44 0x45 0x46 0x47 0x48 0x49 0x4a 0x4b 0x4c 0x4d 0x4e 0x4f 0x50 0x51 0x52 0x53 0x54 0x55 0x56 0x57 0x58 0x59 0x5a 0x5b 0x5c 0x5d 0x5e 0x5f 0x60 0x61 0x62 0x63 0x64 0x65 0x66 0x67 0x68 0x69 0x6a 0x6b 0x6c 0x6d 0x6e 0x6f 0x70 0x71 0x72 0x73 0x74 0x75 0x76 0x77 0x78 0x79 0x7a 0x7b 0x7c 0x7d 0x7e 0x7f 0x80 0x81 0x82 0x83 0x84 0x85 0x86 0x87 0x88 0x89 0x8a 0x8b 0x8c 0x8d 0x8e 0x8f 0x90 0x91 0x92 0x93 0x94 0x95 0x96 0x97 0x98 0x99 0x9a 0x9b 0x9c 0x9d 0x9e 0x9f 0xa0 0xa1 0xa2 0xa3 0xa4 0xa5 0xa6 0xa7 0xa8 0xa9 0xaa 0xab 0xac 0xad 0xae 0xaf 0xb0 0xb1 0xb2 0xb3 0xb4 0xb5 0xb6 0xb7 0xb8 0xb9 0xba 0xbb 0xbc 0xbd 0xbe 0xbf 0xc0 0xc1 0xc2 0xc3 0xc4 0xc5 0xc6 0xc7 0xc8 0xc9 0xca 0xcb 0xcc 0xcd 0xce 0xcf 0xd0 0xd1 0xd2 0xd3 0xd4 0xd5 0xd6 0xd7 0xd8 0xd9 0xda 0xdb 0xdc 0xdd 0xde 0xdf 0xe0 0xe1 0xe2 0xe3 0xe4 0xe5 0xe6 0xe7 0xe8 0xe9 0xea 0xeb 0xec 0xed 0xee 0xef 0xf0 0xf1 0xf2 0xf3 0xf4 0xf5 0xf6 0xf7 0xf8 0xf9 0xfa 0xfb 0xfc 0xfd 0xfe 0xff>;
		default-brightness-level = <0x49>;
		pwms = <0x2e 0x13 0x61a8 0x00>;
		phandle = <0xa1>;
	};

	backlight1 {
		compatible = "pwm-backlight";
		status = "okay";
		brightness-levels = <0x00 0x01 0x02 0x03 0x04 0x05 0x06 0x07 0x08 0x09 0x0a 0x0b 0x0c 0x0d 0x0e 0x0f 0x10 0x11 0x12 0x13 0x14 0x15 0x16 0x17 0x18 0x19 0x1a 0x1b 0x1c 0x1d 0x1e 0x1f 0x20 0x21 0x22 0x23 0x24 0x25 0x26 0x27 0x28 0x29 0x2a 0x2b 0x2c 0x2d 0x2e 0x2f 0x30 0x31 0x32 0x33 0x34 0x35 0x36 0x37 0x38 0x39 0x3a 0x3b 0x3c 0x3d 0x3e 0x3f 0x40 0x41 0x42 0x43 0x44 0x45 0x46 0x47 0x48 0x49 0x4a 0x4b 0x4c 0x4d 0x4e 0x4f 0x50 0x51 0x52 0x53 0x54 0x55 0x56 0x57 0x58 0x59 0x5a 0x5b 0x5c 0x5d 0x5e 0x5f 0x60 0x61 0x62 0x63 0x64 0x65 0x66 0x67 0x68 0x69 0x6a 0x6b 0x6c 0x6d 0x6e 0x6f 0x70 0x71 0x72 0x73 0x74 0x75 0x76 0x77 0x78 0x79 0x7a 0x7b 0x7c 0x7d 0x7e 0x7f 0x80 0x81 0x82 0x83 0x84 0x85 0x86 0x87 0x88 0x89 0x8a 0x8b 0x8c 0x8d 0x8e 0x8f 0x90 0x91 0x92 0x93 0x94 0x95 0x96 0x97 0x98 0x99 0x9a 0x9b 0x9c 0x9d 0x9e 0x9f 0xa0 0xa1 0xa2 0xa3 0xa4 0xa5 0xa6 0xa7 0xa8 0xa9 0xaa 0xab 0xac 0xad 0xae 0xaf 0xb0 0xb1 0xb2 0xb3 0xb4 0xb5 0xb6 0xb7 0xb8 0xb9 0xba 0xbb 0xbc 0xbd 0xbe 0xbf 0xc0 0xc1 0xc2 0xc3 0xc4 0xc5 0xc6 0xc7 0xc8 0xc9 0xca 0xcb 0xcc 0xcd 0xce 0xcf 0xd0 0xd1 0xd2 0xd3 0xd4 0xd5 0xd6 0xd7 0xd8 0xd9 0xda 0xdb 0xdc 0xdd 0xde 0xdf 0xe0 0xe1 0xe2 0xe3 0xe4 0xe5 0xe6 0xe7 0xe8 0xe9 0xea 0xeb 0xec 0xed 0xee 0xef 0xf0 0xf1 0xf2 0xf3 0xf4 0xf5 0xf6 0xf7 0xf8 0xf9 0xfa 0xfb 0xfc 0xfd 0xfe 0xff>;
		default-brightness-level = <0xc8>;
		pwms = <0x1d 0x04 0x61a8 0x00>;
		phandle = <0xa4>;
	};

	lvds_panel@0 {
		compatible = "sunxi-lvds";
		status = "okay";
		power-delay-ms = <0x0a>;
		power0-supply = <0xa0>;
		power1-supply = <0x17>;
		backlight = <0xa1>;
		bus-format = <0x1011>;
		enable0-gpios = <0x14 0x04 0x0e 0x01 0x00 0x03 0x01>;

		display-timings {
			native-mode = <0xa2>;

			timing0 {
				clock-frequency = <0x4767330>;
				hback-porch = <0x46>;
				hactive = <0x500>;
				hfront-porch = <0x53>;
				hsync-len = <0x12>;
				vback-porch = <0x0d>;
				vactive = <0x320>;
				vfront-porch = <0x25>;
				vsync-len = <0x0a>;
				phandle = <0xa2>;
			};

			timing1 {
				clock-frequency = <0x8f05d40>;
				hback-porch = <0x40>;
				hactive = <0x780>;
				hfront-porch = <0x40>;
				hsync-len = <0x10>;
				vback-porch = <0x04>;
				vactive = <0x4b0>;
				vfront-porch = <0x04>;
				vsync-len = <0x03>;
			};
		};

		port {

			endpoint {
				remote-endpoint = <0xa3>;
				phandle = <0x7e>;
			};
		};
	};

	lvds_panel1@0 {
		compatible = "sunxi-lvds";
		status = "disabled";
		power-delay-ms = <0x0a>;
		power0-supply = <0xa0>;
		power1-supply = <0x17>;
		backlight = <0xa4>;
		bus-format = <0x1011>;
		enable0-gpios = <0x14 0x08 0x10 0x01 0x00 0x03 0x01>;

		display-timings {
			native-mode = <0xa5>;

			timing0 {
				clock-frequency = <0x4767330>;
				hback-porch = <0x46>;
				hactive = <0x500>;
				hfront-porch = <0x53>;
				hsync-len = <0x12>;
				vback-porch = <0x0d>;
				vactive = <0x320>;
				vfront-porch = <0x25>;
				vsync-len = <0x0a>;
				phandle = <0xa5>;
			};

			timing1 {
				clock-frequency = <0x8f05d40>;
				hback-porch = <0x40>;
				hactive = <0x780>;
				hfront-porch = <0x40>;
				hsync-len = <0x10>;
				vback-porch = <0x04>;
				vactive = <0x4b0>;
				vfront-porch = <0x04>;
				vsync-len = <0x03>;
			};
		};

		port {

			endpoint {
				remote-endpoint = <0xa6>;
				phandle = <0x82>;
			};
		};
	};

	dsi_panel@0 {
		compatible = "allwinner,panel-dsi";
		status = "disabled";
		power-delay-ms = <0x0a>;
		power0-supply = <0xa0>;
		power1-supply = <0x17>;
		enable0-gpios = <0x14 0x04 0x0e 0x00>;
		backlight = <0xa1>;
		dsi,flags = <0x01>;
		dsi,lanes = <0x04>;
		dsi,format = <0x00>;
		panel-init-sequence = [39 01 04 b9 ff 83 94 39 01 03 ba 73 83 39 01 10 b1 6c 15 15 24 e4 11 f1 80 e4 d7 23 80 c0 d2 58 39 01 0c b2 00 64 10 07 20 1c 08 08 1c 4d 00 39 01 0d b4 00 ff 03 5a 03 5a 03 5a 01 6a 01 6a 39 01 1f d3 00 06 00 40 1a 08 00 32 10 07 00 07 54 15 0f 05 04 02 12 10 05 07 33 33 0b 0b 37 10 07 07 39 01 2d d5 19 19 18 18 1a 1a 1b 1b 04 05 06 07 00 01 02 03 20 21 18 18 18 18 18 18 18 18 18 18 18 18 22 23 18 18 18 18 18 18 18 18 18 18 18 18 39 01 2d d6 18 18 19 19 1a 1a 1b 1b 03 02 01 00 07 06 05 04 23 22 18 18 18 18 18 18 18 18 18 18 18 18 21 20 18 18 18 18 18 18 18 18 18 18 18 18 39 01 2b e0 00 06 0c 31 34 3f 1d 41 06 0a 0c 17 0f 12 15 13 14 07 12 15 16 00 06 0b 30 34 3f 1d 40 07 0a 0d 18 0e 12 14 12 14 08 13 14 19 39 01 03 b6 3a 3a 15 01 02 cc 09 15 01 02 d2 55 39 01 03 c0 30 14 39 01 04 bf 41 0e 01 39 01 05 c7 00 c0 40 c0 15 01 02 df 8e 05 78 01 11 05 14 01 29];
		panel-exit-sequence = <0x5000128 0x5780110>;

		display-timings {
			native-mode = <0xa7>;

			timing0 {
				clock-frequency = <0x4769400>;
				hback-porch = <0x18>;
				hactive = <0x320>;
				hfront-porch = <0x84>;
				hsync-len = <0x04>;
				vback-porch = <0x08>;
				vactive = <0x500>;
				vfront-porch = <0x08>;
				vsync-len = <0x04>;
				phandle = <0xa7>;
			};
		};

		port {

			endpoint@0 {
				reg = <0x00>;
				remote-endpoint = <0xa8>;
				phandle = <0x77>;
			};
		};
	};

	edp_panel {
		compatible = "edp-general-panel";
		status = "okay";
		power0-supply = <0xa0>;
		power1-supply = <0x18>;
		power-delay-ms = <0x32>;
		backlight = <0xa4>;

		ports {
			#address-cells = <0x01>;
			#size-cells = <0x00>;

			port@0 {
				#address-cells = <0x01>;
				#size-cells = <0x00>;
				reg = <0x00>;

				endpoint@0 {
					reg = <0x00>;
					remote-endpoint = <0xa9>;
					phandle = <0x8c>;
				};
			};
		};
	};
};
